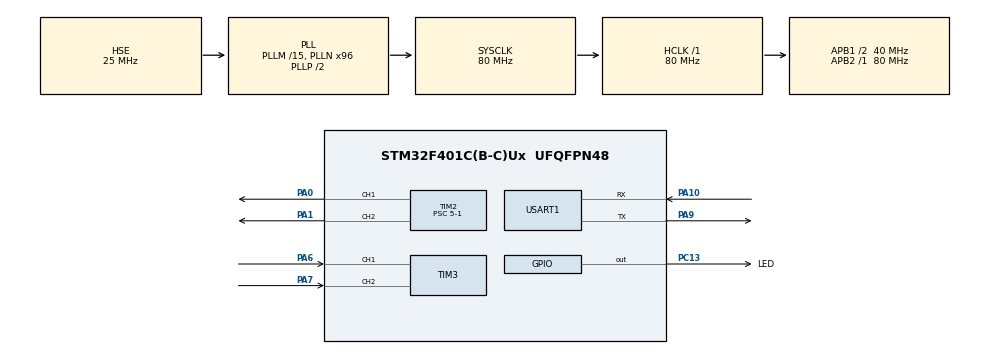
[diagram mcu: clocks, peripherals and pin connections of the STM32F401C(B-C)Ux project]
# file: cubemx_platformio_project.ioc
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Dma.Request0=USART1_TX
Dma.Request1=USART1_RX
Dma.USART1_RX.1.Direction=DMA_PERIPH_TO_MEMORY
Dma.USART1_RX.1.FIFOMode=DMA_FIFOMODE_DISABLE
Dma.USART1_RX.1.Instance=DMA2_Stream5
Dma.USART1_RX.1.MemDataAlignment=DMA_MDATAALIGN_BYTE
Dma.USART1_RX.1.MemInc=DMA_MINC_ENABLE
Dma.USART1_RX.1.Mode=DMA_NORMAL
Dma.USART1_RX.1.PeriphDataAlignment=DMA_PDATAALIGN_BYTE
Dma.USART1_RX.1.PeriphInc=DMA_PINC_DISABLE
Dma.USART1_RX.1.Priority=DMA_PRIORITY_LOW
Dma.USART1_TX.0.Direction=DMA_MEMORY_TO_PERIPH
Dma.USART1_TX.0.FIFOMode=DMA_FIFOMODE_DISABLE
Dma.USART1_TX.0.Instance=DMA2_Stream7
Dma.USART1_TX.0.MemDataAlignment=DMA_MDATAALIGN_BYTE
Dma.USART1_TX.0.MemInc=DMA_MINC_ENABLE
Dma.USART1_TX.0.Mode=DMA_NORMAL
Dma.USART1_TX.0.PeriphDataAlignment=DMA_PDATAALIGN_BYTE
Dma.USART1_TX.0.PeriphInc=DMA_PINC_DISABLE
Dma.USART1_TX.0.Priority=DMA_PRIORITY_LOW
Mcu.Family=STM32F4
Mcu.Name=STM32F401C(B-C)Ux
Mcu.Package=UFQFPN48
NVIC.DMA2_Stream5_IRQn=true\:0\:0\:false\:false\:true\:false\:true\:true
NVIC.DMA2_Stream7_IRQn=true\:0\:0\:false\:false\:true\:false\:true\:true
NVIC.PriorityGroup=NVIC_PRIORITYGROUP_4
PA0-WKUP.Signal=S_TIM2_CH1_ETR
PA1.Signal=S_TIM2_CH2
PA10.Mode=Asynchronous
PA10.Signal=USART1_RX
PA13.Mode=Trace_Asynchronous_SW
PA13.Signal=SYS_JTMS-SWDIO
PA14.Mode=Trace_Asynchronous_SW
PA14.Signal=SYS_JTCK-SWCLK
PA6.Signal=S_TIM3_CH1
PA7.Signal=S_TIM3_CH2
PA9.Mode=Asynchronous
PA9.Signal=USART1_TX
PB3.Mode=Trace_Asynchronous_SW
PB3.Signal=SYS_JTDO-SWO
PC13-ANTI_TAMP.GPIO_Label=LED
PC13-ANTI_TAMP.Signal=GPIO_Output
PH0\ -\ OSC_IN.Mode=HSE-External-Oscillator
PH0\ -\ OSC_IN.Signal=RCC_OSC_IN
PH1\ -\ OSC_OUT.Mode=HSE-External-Oscillator
PH1\ -\ OSC_OUT.Signal=RCC_OSC_OUT
ProjectManager.HeapSize=0x200
ProjectManager.StackSize=0x400
ProjectManager.TargetToolchain=EWARM V8.50
RCC.48MHZClocksFreq_Value=40000000
RCC.AHBFreq_Value=80000000
RCC.APB1CLKDivider=RCC_HCLK_DIV2
RCC.APB1Freq_Value=40000000
RCC.APB1TimFreq_Value=80000000
RCC.APB2Freq_Value=80000000
RCC.APB2TimFreq_Value=80000000
RCC.CortexFreq_Value=80000000
RCC.HCLKFreq_Value=80000000
RCC.HSE_VALUE=25000000
RCC.HSI_VALUE=16000000
RCC.LSE_VALUE=32768
RCC.PLLM=15
RCC.PLLN=96
RCC.PLLSourceVirtual=RCC_PLLSOURCE_HSE
RCC.SYSCLKFreq_VALUE=80000000
RCC.SYSCLKSource=RCC_SYSCLKSOURCE_PLLCLK
RCC.VCOOutputFreq_Value=160000000
SH.S_TIM2_CH1_ETR.0=TIM2_CH1,PWM Generation1 CH1
SH.S_TIM2_CH2.0=TIM2_CH2,PWM Generation2 CH2
SH.S_TIM3_CH1.0=TIM3_CH1,Encoder_Interface
SH.S_TIM3_CH2.0=TIM3_CH2,Encoder_Interface
TIM2.Channel-PWM\ Generation1\ CH1=TIM_CHANNEL_1
TIM2.Channel-PWM\ Generation2\ CH2=TIM_CHANNEL_2
TIM2.Period=1000
TIM2.Prescaler=5-1
USART1.VirtualMode=VM_ASYNC
VP_TIM2_VS_ClockSourceINT.Mode=Internal
board=custom

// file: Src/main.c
/* USER CODE BEGIN Header */
/**
 ******************************************************************************
 * @file           : main.c
 * @brief          : Main program body
 ******************************************************************************
 * @attention
 *
 * Copyright (c) 2023 STMicroelectronics.
 * All rights reserved.
 *
 * This software is licensed under terms that can be found in the LICENSE file
 * in the root directory of this software component.
 * If no LICENSE file comes with this software, it is provided AS-IS.
 *
 ******************************************************************************
 */
/* USER CODE END Header */
#include "main.h"
#include "dma.h"
#include "gpio.h"
#include "tim.h"
#include "usart.h"

/* USER CODE BEGIN Includes */

#include "user_app.h"
#include <stdio.h>
/* USER CODE END Includes */

void SystemClock_Config(void);

int main(void) {

    /* MCU Configuration--------------------------------------------------------*/

    /* Reset of all peripherals, Initializes the Flash interface and the Systick.
     */
    HAL_Init();

    /* Configure the system clock */
    SystemClock_Config();

    /* Initialize all configured peripherals */
    MX_GPIO_Init();
    MX_DMA_Init();
    MX_TIM2_Init();
    MX_TIM3_Init();
    MX_USART1_UART_Init();
    /* USER CODE BEGIN 2 */
    user_app_init();

    /* USER CODE END 2 */

    /* Infinite loop */
    while (1) {
        // user_app_main();

    }
}

void SystemClock_Config(void) {
    RCC_OscInitTypeDef RCC_OscInitStruct = { 0 };
    RCC_ClkInitTypeDef RCC_ClkInitStruct = { 0 };

    /** Configure the main internal regulator output voltage
     */
    __HAL_RCC_PWR_CLK_ENABLE();
    __HAL_PWR_VOLTAGESCALING_CONFIG(PWR_REGULATOR_VOLTAGE_SCALE2);

    /** Initializes the RCC Oscillators according to the specified parameters
     * in the RCC_OscInitTypeDef structure.
     */
    RCC_OscInitStruct.OscillatorType = RCC_OSCILLATORTYPE_HSE;
    RCC_OscInitStruct.HSEState = RCC_HSE_ON;
    RCC_OscInitStruct.PLL.PLLState = RCC_PLL_ON;
    RCC_OscInitStruct.PLL.PLLSource = RCC_PLLSOURCE_HSE;
    RCC_OscInitStruct.PLL.PLLM = 15;
    RCC_OscInitStruct.PLL.PLLN = 96;
    RCC_OscInitStruct.PLL.PLLP = RCC_PLLP_DIV2;
    RCC_OscInitStruct.PLL.PLLQ = 4;
    if (HAL_RCC_OscConfig(&RCC_OscInitStruct) != HAL_OK) {
        Error_Handler();
    }

    /** Initializes the CPU, AHB and APB buses clocks
     */
    RCC_ClkInitStruct.ClockType = RCC_CLOCKTYPE_HCLK | RCC_CLOCKTYPE_SYSCLK | RCC_CLOCKTYPE_PCLK1 | RCC_CLOCKTYPE_PCLK2;
    RCC_ClkInitStruct.SYSCLKSource = RCC_SYSCLKSOURCE_PLLCLK;
    RCC_ClkInitStruct.AHBCLKDivider = RCC_SYSCLK_DIV1;
    RCC_ClkInitStruct.APB1CLKDivider = RCC_HCLK_DIV2;
    RCC_ClkInitStruct.APB2CLKDivider = RCC_HCLK_DIV1;

    if (HAL_RCC_ClockConfig(&RCC_ClkInitStruct, FLASH_LATENCY_2) != HAL_OK) {
        Error_Handler();
    }
}

void Error_Handler(void) {
    __disable_irq();
    while (1) {
    }
}

#ifdef USE_FULL_ASSERT
/**
 * @brief  Reports the name of the source file and the source line number
 *         where the assert_param error has occurred.
 * @param  file: pointer to the source file name
 * @param  line: assert_param error line source number
 * @retval None
 */
void assert_failed(uint8_t* file, uint32_t line) {
    /* USER CODE BEGIN 6 */
    /* User can add his own implementation to report the file name and line
       number, ex: printf("Wrong parameters value: file %s on line %d\r\n", file,
       line) */
    /* USER CODE END 6 */
}
#endif /* USE_FULL_ASSERT */
